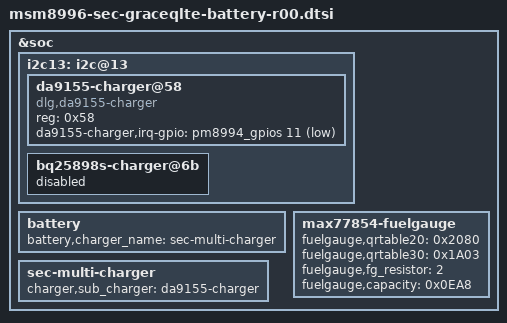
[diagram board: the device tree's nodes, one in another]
/* Copyright (c) 2014, The Linux Foundation. All rights reserved.
 *
 * This program is free software; you can redistribute it and/or modify
 * it under the terms of the GNU General Public License version 2 and
 * only version 2 as published by the Free Software Foundation.
 *
 * This program is distributed in the hope that it will be useful,
 * but WITHOUT ANY WARRANTY; without even the implied warranty of
 * MERCHANTABILITY or FITNESS FOR A PARTICULAR PURPOSE.  See the
 * GNU General Public License for more details.
 */
#include "msm8996-sec-graceqlte-common-battery.dtsi"
&soc {
	i2c13: i2c@13 {
	       da9155-charger@58 {
		       compatible = "dlg,da9155-charger";
		       reg = <0x58>;
		       da9155-charger,irq-gpio = <&pm8994_gpios 11 0x1>;
	       };
	       bq25898s-charger@6b {
		       status = "disabled";
	       };
	};
	battery {
		battery,charger_name = "sec-multi-charger";
	};

	sec-multi-charger {
		charger,sub_charger = "da9155-charger";
	};

	max77854-fuelgauge {
		fuelgauge,qrtable20 = <0x2080>;
		fuelgauge,qrtable30 = <0x1A03>;
		fuelgauge,fg_resistor = <2>;
		fuelgauge,capacity = <0x0EA8>;
	};
};
